AUTOSAR XML (schema 314)
package /ComponentType
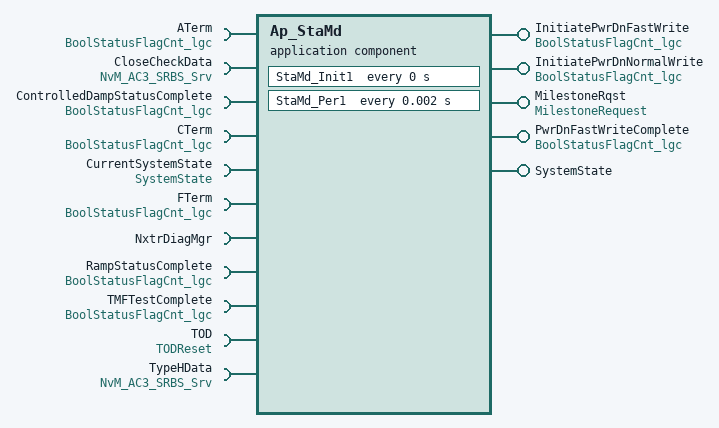
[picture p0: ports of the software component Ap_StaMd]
  application software component type Ap_StaMd
    5 x provide port:
      InitiatePwrDnFastWrite: unqueued-sender-com-spec{data-element=Cnt_lgc, can-invalidate=false, init-value=D_FALSE_CNT_LGC}, provided-interface=BoolStatusFlagCnt_lgc
      InitiatePwrDnNormalWrite: unqueued-sender-com-spec{data-element=Cnt_lgc, can-invalidate=false, init-value=D_FALSE_CNT_LGC}, provided-interface=BoolStatusFlagCnt_lgc
      MilestoneRqst: provided-interface=MilestoneRequest
        provided-com-specs:
          operation=WarmInitMilestoneComplete, queue-length=1
          operation=WarmInitMilestoneNotComplete, queue-length=1
      PwrDnFastWriteComplete: unqueued-sender-com-spec{data-element=Cnt_lgc, can-invalidate=false, init-value=D_FALSE_CNT_LGC}, provided-interface=BoolStatusFlagCnt_lgc
      SystemState: mode-switch-com-spec{mode-group=Mode, queue-length=1}, provided-interface=SystemState
    11 x require port:
      ATerm: unqueued-receiver-com-spec{data-element=Cnt_lgc, init-value=D_TRUE_CNT_LGC}, required-interface=BoolStatusFlagCnt_lgc
      CloseCheckData: required-com-specs=[EraseBlock, GetErrorStatus, InvalidateNvBlock, ReadBlock, SetRamBlockStatus, WriteBlock], required-interface=NvM_AC3_SRBS_Srv
      ControlledDampStatusComplete: unqueued-receiver-com-spec{data-element=Cnt_lgc, init-value=D_FALSE_CNT_LGC}, required-interface=BoolStatusFlagCnt_lgc
      CTerm: unqueued-receiver-com-spec{data-element=Cnt_lgc, init-value=D_FALSE_CNT_LGC}, required-interface=BoolStatusFlagCnt_lgc
      CurrentSystemState: required-interface=SystemState
      FTerm: unqueued-receiver-com-spec{data-element=Cnt_lgc, init-value=D_FALSE_CNT_LGC}, required-interface=BoolStatusFlagCnt_lgc
      NxtrDiagMgr: required-com-specs=[GetNTCActive, GetNTCFailed, GetNTCStatus, SetNTCStatus], required-interface=NxtrDiagMgr
      RampStatusComplete: unqueued-receiver-com-spec{data-element=Cnt_lgc, init-value=D_FALSE_CNT_LGC}, required-interface=BoolStatusFlagCnt_lgc
      TMFTestComplete: unqueued-receiver-com-spec{data-element=Cnt_lgc, init-value=D_FALSE_CNT_LGC}, required-interface=BoolStatusFlagCnt_lgc
      TOD: client-com-spec=OP_SET, required-interface=TODReset
      TypeHData: required-com-specs=[EraseBlock, GetErrorStatus, InvalidateNvBlock, ReadBlock, SetRamBlockStatus, WriteBlock], required-interface=NvM_AC3_SRBS_Srv
  internal behavior Ap_StaMd_InternalBehavior: component=Ap_StaMd
    operation invoked event OIT_MilestoneRqst_WarmInitMilestoneComplete_MilestoneRqst_WarmInitMilestoneComplete: start-on-event=MilestoneRqst_WarmInitMilestoneComplete, operation=MilestoneRqst.WarmInitMilestoneComplete
    operation invoked event OIT_MilestoneRqst_WarmInitMilestoneNotComplete_MilestoneRqst_WarmInitMilestoneNotComplete: start-on-event=MilestoneRqst_WarmInitMilestoneNotComplete, operation=MilestoneRqst.WarmInitMilestoneNotComplete
    timing event StaMd_Init1_InitEvent: start-on-event=StaMd_Init1, period=0
    timing event TMT_StaMd_Per1: start-on-event=StaMd_Per1, period=0.002
    mode switch event MST_StaMd_Trns1_0: start-on-event=StaMd_Trns1, activation=ENTRY, mode=CurrentSystemState.Mode.OFF
    exclusive area StaMds_MilestoneRqst_WARMINIT_ExclArea
    port-api-options:
      enable-take-address=false, indirect-api=false, port=ATerm
      enable-take-address=false, indirect-api=false, port=CloseCheckData
      enable-take-address=false, indirect-api=false, port=ControlledDampStatusComplete
      enable-take-address=false, indirect-api=false, port=CTerm
      enable-take-address=false, indirect-api=false, port=CurrentSystemState
      enable-take-address=false, indirect-api=false, port=FTerm
      enable-take-address=false, indirect-api=false, port=InitiatePwrDnFastWrite
      enable-take-address=false, indirect-api=false, port=InitiatePwrDnNormalWrite
      enable-take-address=false, indirect-api=false, port=MilestoneRqst
      enable-take-address=false, indirect-api=false, port=NxtrDiagMgr
      enable-take-address=false, indirect-api=false, port=PwrDnFastWriteComplete
      enable-take-address=false, indirect-api=false, port=RampStatusComplete
      enable-take-address=false, indirect-api=false, port=SystemState
      enable-take-address=false, indirect-api=false, port=TMFTestComplete
      enable-take-address=false, indirect-api=false, port=TOD
      enable-take-address=false, indirect-api=false, port=TypeHData
    5 x runnable:
      MilestoneRqst_WarmInitMilestoneComplete: can-be-invoked-concurrently=true, can-enter-exclusive-area=StaMds_MilestoneRqst_WARMINIT_ExclArea
      MilestoneRqst_WarmInitMilestoneNotComplete: can-be-invoked-concurrently=true, can-enter-exclusive-area=StaMds_MilestoneRqst_WARMINIT_ExclArea
      StaMd_Init1
        sync call SC_CloseCheckData_WriteBlock: operation=CloseCheckData.WriteBlock, timeout=0
        sync call SC_NxtrDiagMgr_SetNTCStatus: operation=NxtrDiagMgr.SetNTCStatus, timeout=0
      StaMd_Per1
        6 x data read access:
          READ_ATerm_Cnt_lgc: data-element=ATerm.Cnt_lgc
          READ_ControlledDampStatusComplete_Cnt_lgc: data-element=ControlledDampStatusComplete.Cnt_lgc
          READ_CTerm_Cnt_lgc: data-element=CTerm.Cnt_lgc
          READ_FTerm_Cnt_lgc: data-element=FTerm.Cnt_lgc
          READ_RampStatusComplete_Cnt_lgc: data-element=RampStatusComplete.Cnt_lgc
          READ_TMFTestComplete_Cnt_lgc: data-element=TMFTestComplete.Cnt_lgc
        data send point SEND_InitiatePwrDnFastWrite_Cnt_lgc: data-element=InitiatePwrDnFastWrite.Cnt_lgc
        data send point SEND_InitiatePwrDnNormalWrite_Cnt_lgc: data-element=InitiatePwrDnNormalWrite.Cnt_lgc
        data send point SEND_PwrDnFastWriteComplete_Cnt_lgc: data-element=PwrDnFastWriteComplete.Cnt_lgc
        mode switch point SWITCH_SystemState_Mode: mode-group=SystemState.Mode
        sync call SC_CloseCheckData_GetErrorStatus: operation=CloseCheckData.GetErrorStatus, timeout=0
        sync call SC_CloseCheckData_WriteBlock: operation=CloseCheckData.WriteBlock, timeout=0
        sync call SC_TOD_OP_SET: operation=TOD.OP_SET, timeout=0
      StaMd_Trns1
        data send point SEND_InitiatePwrDnFastWrite_Cnt_lgc: data-element=InitiatePwrDnFastWrite.Cnt_lgc
        data send point SEND_InitiatePwrDnNormalWrite_Cnt_lgc: data-element=InitiatePwrDnNormalWrite.Cnt_lgc
        sync call SC_TypeHData_WriteBlock: operation=TypeHData.WriteBlock, timeout=0
  swc implementation Ap_StaMd_Implementation: behavior=Ap_StaMd_InternalBehavior
    code-descriptors:
      code Code: type=SRC
